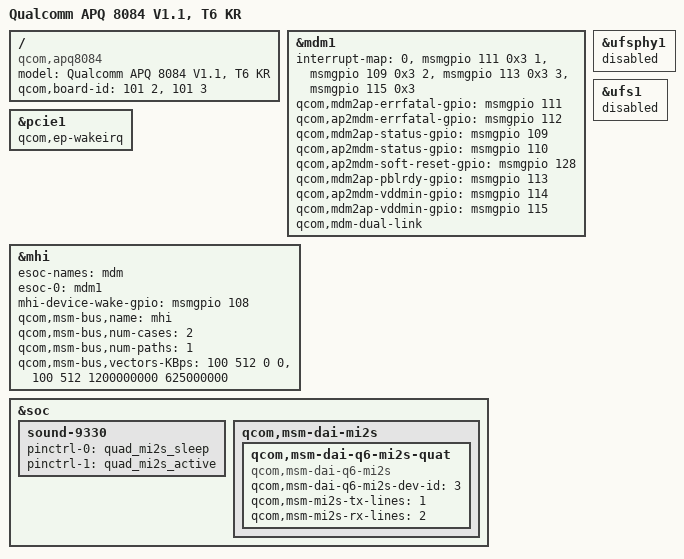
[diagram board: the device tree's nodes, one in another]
/* Copyright (c) 2013-2014, The Linux Foundation. All rights reserved.
 *
 * This program is free software; you can redistribute it and/or modify
 * it under the terms of the GNU General Public License version 2 and
 * only version 2 as published by the Free Software Foundation.
 *
 * This program is distributed in the hope that it will be useful,
 * but WITHOUT ANY WARRANTY; without even the implied warranty of
 * MERCHANTABILITY or FITNESS FOR A PARTICULAR PURPOSE.  See the
 * GNU General Public License for more details.
 */

/dts-v1/;

#include "../apq8084-lge-common/apq8084-v1-1-lge.dtsi"
#include "apq8084-t6-kr.dtsi"

/ {
	model = "Qualcomm APQ 8084 V1.1, T6 KR";
	compatible = "qcom,apq8084";
	qcom,board-id = <101 2>,
			<101 3>;
};

&mdm1 {
	interrupt-map = <0 &msmgpio 111 0x3
			1 &msmgpio 109 0x3
			2 &msmgpio 113 0x3
			3 &msmgpio 115 0x3>;
	qcom,mdm2ap-errfatal-gpio = <&msmgpio 111 0x00>;
	qcom,ap2mdm-errfatal-gpio = <&msmgpio 112 0x00>;
	qcom,mdm2ap-status-gpio   = <&msmgpio 109 0x00>;
	qcom,ap2mdm-status-gpio   = <&msmgpio 110 0x00>;
	qcom,ap2mdm-soft-reset-gpio = <&msmgpio 128 0x00>;
	qcom,mdm2ap-pblrdy-gpio = <&msmgpio 113 0x00>;
	qcom,ap2mdm-vddmin-gpio = <&msmgpio 114 0x00>;
	qcom,mdm2ap-vddmin-gpio = <&msmgpio 115 0x00>;
	qcom,mdm-dual-link;
	status = "ok";
};

&pcie1 {
	qcom,ep-wakeirq;
};

&mhi {
	esoc-names = "mdm";
	esoc-0 = <&mdm1>;
	mhi-device-wake-gpio =
		<&msmgpio 108 0>;
	qcom,msm-bus,name = "mhi";
	qcom,msm-bus,num-cases = <2>;
	qcom,msm-bus,num-paths = <1>;
	qcom,msm-bus,vectors-KBps =
			<100 512 0 0>,
			<100 512 1200000000 625000000>;

	/delete-property/compatible;
};

&ufsphy1 {
	status = "disabled";
};

&ufs1 {
	status = "disabled";
};

&soc {
	sound-9330 {
		pinctrl-names = "pmx-quad-mi2s-sleep",
				"pmx-quad-mi2s-active";
		pinctrl-0 = <&quad_mi2s_sleep>;
		pinctrl-1 = <&quad_mi2s_active>;
	};

	qcom,msm-dai-mi2s {
		qcom,msm-dai-q6-mi2s-quat {
			compatible = "qcom,msm-dai-q6-mi2s";
			qcom,msm-dai-q6-mi2s-dev-id = <3>;
			qcom,msm-mi2s-tx-lines = <1>;
			qcom,msm-mi2s-rx-lines = <2>;
		};
	};
};
